# CY8C5888LTI_LP097 register map
File version: 0.1
Registers are 8-bit, read-write, no defined reset value unless marked. A register's access mark holds for its fields unless they carry their own. Offsets are from the block's base; [hi:lo] are bit positions; {n}, {i} and the like mark numbered series.

## I2S_Codec_audio
Base 0x00000000
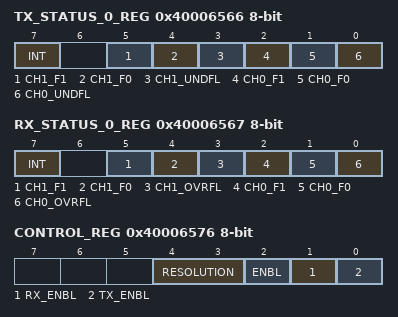
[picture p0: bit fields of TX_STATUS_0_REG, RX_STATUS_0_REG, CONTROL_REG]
0x40006566 TX_STATUS_0_REG
  [7] INT ro — Interrupt bit
  [5] CH1_F1 ro — Stereo channel 1 FIFO 1 state
    0=FULL; 1=NOT_FULL
  [4] CH1_F0 ro — Stereo channel 1 FIFO 0 state
    0=FULL; 1=NOT_FULL
  [3] CH1_UNDFL ro — Stereo channel 1 FIFO underflow
    0=NO_UNDERFLOW; 1=UNDERFLOW
  [2] CH0_F1 ro — Stereo channel 0 FIFO 1 state
    0=FULL; 1=NOT_FULL
  [1] CH0_F0 ro — Stereo channel 0 FIFO 0 state
    0=FULL; 1=NOT_FULL
  [0] CH0_UNDFL ro — Stereo channel 0 FIFO underflow
    0=NO_UNDERFLOW; 1=UNDERFLOW
0x40006567 RX_STATUS_0_REG
  [7] INT ro — Interrupt bit
  [5] CH1_F1 ro — Stereo channel 1 FIFO 1 state
    0=EMPTY; 1=NOT_EMPTY
  [4] CH1_F0 ro — Stereo channel 1 FIFO 0 state
    0=EMPTY; 1=NOT_EMPTY
  [3] CH1_OVRFL ro — Stereo channel 1 FIFO overflow
    0=NO_OVERFLOW; 1=OVERFLOW
  [2] CH0_F1 ro — Stereo channel 0 FIFO 1 state
    0=EMPTY; 1=NOT_EMPTY
  [1] CH0_F0 ro — Stereo channel 0 FIFO 0 state
    0=EMPTY; 1=NOT_EMPTY
  [0] CH0_OVRFL ro — Stereo channel 0 FIFO overflow
    0=NO_OVERFLOW; 1=OVERFLOW
0x40006576 CONTROL_REG
  [4:3] RESOLUTION — Specifies data bits value. Applicable only if dynamic bit resolution is selected.
    0=Cy8_BIT; 1=Cy16_BIT; 2=Cy24_BIT; 3=Cy32_BIT
  [2] ENBL — Starts the generation of the WS and SCK outputs.
    1=ENABLED; 0=DISABLED
  [1] RX_ENBL — Enables Rx direction. Applicable only if Rx direction presents for the component.
    1=ENABLED; 0=DISABLED
  [0] TX_ENBL — Enables Tx direction. Applicable only if Tx direction presents for the component.
    1=ENABLED; 0=DISABLED

## LEDs
Base 0x40006473
0x00 LEDs_CONTROL_REG

## I2S_EN
Base 0x40006476
Registers as LEDs (with LEDs read as I2S_EN).

## CLIP
Base 0x40006578
Registers as LEDs (with LEDs read as CLIP).

## VOL — SAR ADC
Base 0x00000000
0x40004616 SAR_TR0 — SAR trim register
{0x40005908+i} SAR_CSR{i} (i=0..6) — SAR status and control register {i}
0x40005B28 SAR_SW0 — SAR Analog Routing Register 0
{0x40005B28+i} SAR_SW{i} (i=2..4) — SAR Analog Routing Register {i}
0x40005B2E SAR_SW6 — SAR Analog Routing Register 6
0x40005B2F SAR_CLK — SAR Clock Selection Register
0x40005BA2 SAR_WRK 16-bit — SAR working register

## LINE — SAR ADC
Base 0x00000000
0x40004614 SAR_TR0 — SAR trim register
{0x40005900+i} SAR_CSR{i} (i=0..6) — SAR status and control register {i}
0x40005B20 SAR_SW0 — SAR Analog Routing Register 0
{0x40005B20+i} SAR_SW{i} (i=2..4) — SAR Analog Routing Register {i}
0x40005B26 SAR_SW6 — SAR Analog Routing Register 6
0x40005B27 SAR_CLK — SAR Clock Selection Register
0x40005BA0 SAR_WRK 16-bit — SAR working register

## I2C_Codec_control
Base 0x00000000
0x40006403 I2C_Codec_control_DATA — I2C Data Register
  [7:0] data — Read received data or write data to transmit.
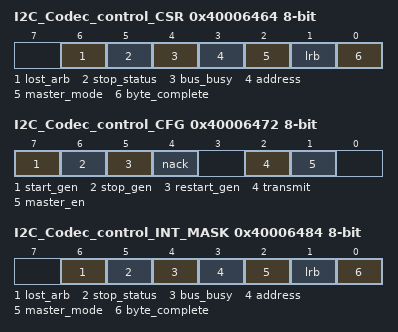
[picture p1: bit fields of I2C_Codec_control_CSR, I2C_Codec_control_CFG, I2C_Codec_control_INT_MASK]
0x40006464 I2C_Codec_control_CSR — I2C Status Register
  [6] lost_arb ro — If set, indicates arbitration was lost (multi-master and multi-master-slave modes).
  [5] stop_status ro — If set, indicates a Stop condition was detected on the bus.
  [4] bus_busy ro — If set, indicates the bus is busy. Data is currently being transmitted or received.
  [3] address ro — Address detection. If set, indicates that an address byte was sent.
  [2] master_mode ro — Indicates that a valid Start condition was generated and a hardware device is operating as bus master.
  [1] lrb ro — Last Received Bit. Indicates the state of the last received bit, which is the ACK/NAK received for the last byte transmitted. Cleared = ACK and set = NAK.
  [0] byte_complete ro — Transmit or receive status since the last read of this register. In Transmit mode this bit indicates that eight bits of data plus ACK/NAK have been transmitted since the last read. In Receive mode this bit indicates that eight bits of data have been received since the last read of this register.
0x40006472 I2C_Codec_control_CFG — I2C Configuration Register
  [7] start_gen — Set to 1 to generate a Start condition on the bus. This bit must be cleared by firmware before initiating the next transaction.
  [6] stop_gen — Set to 1 to generate a Stop condition on the bus. This bit must be cleared by firmware before initiating the next transaction.
  [5] restart_gen — Set to 1 to generate a Restart condition on the bus. This bit must be cleared by firmware after a Restart condition is generated.
  [4] nack — Set to 1 to NAK the next read byte. Clear to ACK next read byte. This bit must be cleared by firmware between bytes.
  [2] transmit — Set to 1 to set the current mode to transmit or clear to 0 to receive a byte of data. This bit must be cleared by firmware before starting the next transmit or receive transaction.
  [1] master_en — Set to 1 to enable the master functionality.
0x40006484 I2C_Codec_control_INT_MASK — I2C Interrupt Enable Mask
  [6] lost_arb — Enables interrupt from the corresponding bit in status register.
  [5] stop_status — Enables interrupt from the corresponding bit in status register.
  [4] bus_busy — Enables interrupt from the corresponding bit in status register.
  [3] address — Enables interrupt from the corresponding bit in status register.
  [2] master_mode — Enables interrupt from the corresponding bit in status register.
  [1] lrb — Enables interrupt from the corresponding bit in status register.
  [0] byte_complete — Enables interrupt from the corresponding bit in status register.
